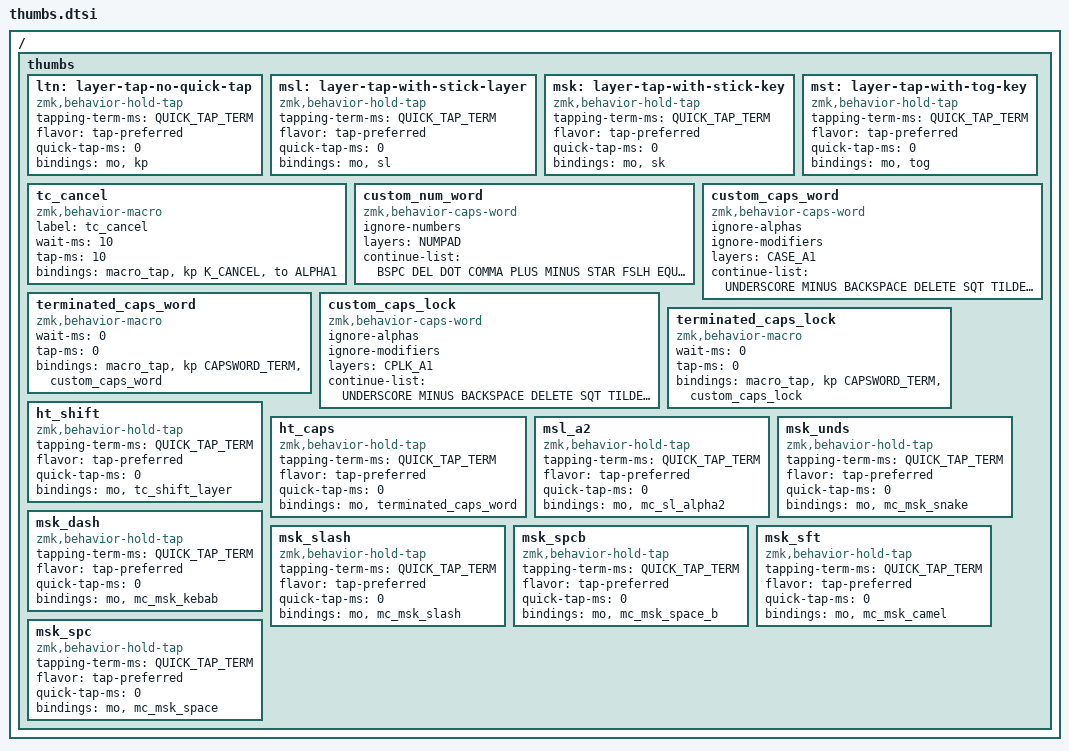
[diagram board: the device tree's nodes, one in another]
/*
*
* Copyright (c) 2022 Rafael Romão
* SPDX-License-Identifier: MIT
*
*/

/ {
    #define THUMB_LAYERTAP(NAME, BINDINGS) \
         NAME: NAME { \
            compatible = "zmk,behavior-hold-tap"; \
            #binding-cells = <2>; \
            tapping-term-ms = <QUICK_TAP_TERM>; \
            flavor = "tap-preferred"; \
            quick-tap-ms = <0>; \
            require-prior-idle-ms = <QUICK_TAP_TERM>; \
            bindings = <&mo>, <BINDINGS>; \
        };

    #define THUMB_MACRO(NAME, BINDINGS) \
        NAME: NAME { \
			compatible = "zmk,behavior-macro"; \
            #binding-cells = <0>; \
            wait-ms = <10>; \
            tap-ms = <10>; \
            bindings = <&macro_tap BINDINGS>; \
        };

    #define THUMB_MORPH(NAME, MODS, MODDED, UNMODDED) \
        NAME: NAME { \
            compatible = "zmk,behavior-mod-morph"; \
            #binding-cells = <0>; \
            bindings = <UNMODDED>, <MODDED>; \
            mods = <(MODS)>; \
        };

    #define THUMB_COMBO_MORPH(NAME, FIRST_MOD, SECOND_MOD, IF_BOTH, OR_ELSE) \
        NAME##_CHECK_SECOND: NAME##_CHECK_SECOND { \
            compatible = "zmk,behavior-mod-morph"; \
            #binding-cells = <0>; \
            bindings = <OR_ELSE>, <IF_BOTH>; \
            mods = <(SECOND_MOD)>; \
        }; \
        NAME: NAME { \
            compatible = "zmk,behavior-mod-morph"; \
            #binding-cells = <0>; \
            bindings = <OR_ELSE>, <&NAME##_CHECK_SECOND>; \
            mods = <(FIRST_MOD)>; \
        };

    thumbs {
        
        // ********************** CUSTOM HOLD TAPS ********************** //

        ltn: layer-tap-no-quick-tap {
            compatible = "zmk,behavior-hold-tap";
            #binding-cells = <2>;
            tapping-term-ms = <QUICK_TAP_TERM>;
            flavor = "tap-preferred";
            quick-tap-ms = <0>;
            bindings = <&mo>, <&kp>;
        };
        msl: layer-tap-with-stick-layer {
            compatible = "zmk,behavior-hold-tap";
            #binding-cells = <2>;
            tapping-term-ms = <QUICK_TAP_TERM>;
            flavor = "tap-preferred";
            quick-tap-ms = <0>;
            bindings = <&mo>, <&sl>;
        };
        msk: layer-tap-with-stick-key {
            compatible = "zmk,behavior-hold-tap";
            #binding-cells = <2>;
            tapping-term-ms = <QUICK_TAP_TERM>;
            flavor = "tap-preferred";
            quick-tap-ms = <0>;
            bindings = <&mo>, <&sk>;
        };
        mst: layer-tap-with-tog-key {
            compatible = "zmk,behavior-hold-tap";
            #binding-cells = <2>;
            tapping-term-ms = <QUICK_TAP_TERM>;
            flavor = "tap-preferred";
            quick-tap-ms = <0>;
            bindings = <&mo>, <&tog>;
        };

        // ********************** SENTENCE CASE ********************** //

        tc_cancel: tc_cancel {
			compatible = "zmk,behavior-macro";
            label = "tc_cancel";
            #binding-cells = <0>;
            wait-ms = <10>;
            tap-ms = <10>;
            bindings = <&macro_tap &kp K_CANCEL &to ALPHA1>;
        };
        THUMB_MACRO(tc_sp_ns,         &kp SPACE &sl SEN_E1)
        THUMB_MACRO(tc_nsen,          &sl SEN_E1)
        THUMB_LAYERTAP(th_sp_ns,      &tc_sp_ns)
        THUMB_LAYERTAP(th_cancel,     &tc_cancel)
        THUMB_LAYERTAP(th_nsen,       &tc_nsen)

        // ********************** NUM WORD ********************** //

        custom_num_word: custom_num_word {
            compatible = "zmk,behavior-caps-word";
            ignore-numbers;
			#binding-cells = <0>;
            layers = <NUMPAD>;
            continue-list = <BSPC DEL DOT COMMA PLUS MINUS STAR FSLH EQUAL MOVE_LEFT MOVE_RIGHT MOVE_UP MOVE_DOWN SCRL_DOWN SCRL_UP RCLK LCLK>;
        };

        THUMB_MACRO(tc_custom_num_word, &to ALPHA1 &custom_num_word)

        // ******************* CAPS WORD ******************* //

        custom_caps_word: custom_caps_word {
            compatible = "zmk,behavior-caps-word";
            ignore-alphas;
            ignore-modifiers;
			#binding-cells = <0>;  
            layers = <CASE_A1>;
            continue-list = <UNDERSCORE MINUS BACKSPACE DELETE SQT TILDE CARET GRAVE>;
        };
        terminated_caps_word: terminated_caps_word {
			compatible = "zmk,behavior-macro";
            #binding-cells = <0>;
            wait-ms = <0>;
            tap-ms = <0>;
            bindings = <&macro_tap &kp CAPSWORD_TERM &custom_caps_word>;
        };

        custom_caps_lock: custom_caps_lock {
            compatible = "zmk,behavior-caps-word";
            ignore-alphas;
            ignore-modifiers;
			#binding-cells = <0>;  
            layers = <CPLK_A1>;
            continue-list = <UNDERSCORE MINUS BACKSPACE DELETE SQT TILDE CARET GRAVE SPACE>;
        };
        terminated_caps_lock: terminated_caps_lock {
			compatible = "zmk,behavior-macro";
            #binding-cells = <0>;
            wait-ms = <0>;
            tap-ms = <0>;
            bindings = <&macro_tap &kp CAPSWORD_TERM &custom_caps_lock>;
        };

        THUMB_MACRO(tc_shift_layer, &sl SHIFT_A1)
        THUMB_MACRO(tc_sp_caps,     &kp LS(SPACE))
        THUMB_LAYERTAP(th_sp_caps,  &tc_sp_caps)

        ht_shift: ht_shift {
            compatible = "zmk,behavior-hold-tap";
            #binding-cells = <2>;
            tapping-term-ms = <QUICK_TAP_TERM>;
            flavor = "tap-preferred";
            quick-tap-ms = <0>;
            bindings = <&mo>, <&tc_shift_layer>;
        };

        ht_caps: ht_caps {
            compatible = "zmk,behavior-hold-tap";
            #binding-cells = <2>;
            tapping-term-ms = <QUICK_TAP_TERM>;
            flavor = "tap-preferred";
            quick-tap-ms = <0>;
            bindings = <&mo>, <&terminated_caps_word>;
        };

        // ******************** SMART CASES ******************** //

        THUMB_MACRO(mc_sl_alpha2,  &enforced_a2)

        THUMB_LAYERTAP(th_sft_a2,  &enforced_a2_s)
        THUMB_LAYERTAP(th_case_a2,  &enforced_a2_c)

        msl_a2: msl_a2 {
            compatible = "zmk,behavior-hold-tap";
            #binding-cells = <2>;
            tapping-term-ms = <QUICK_TAP_TERM>;
            flavor = "tap-preferred";
            quick-tap-ms = <0>;
            bindings = <&mo>, <&mc_sl_alpha2>;
        };

        THUMB_MACRO(tc_shift_camel     ,  &to CAMEL_CASE &sl SHIFT_A1)
        THUMB_MACRO(tc_strong_snakecase,  &tog CASE_A1 &tog SNAKE_CASE)
        THUMB_MACRO(tc_strong_kebabcase,  &tog CASE_A1 &tog KEBAB_CASE)
        THUMB_MACRO(tc_strong_slashcase,  &tog CASE_A1 &tog SLASH_CASE)

        THUMB_MORPH(sc_caps_word,  MOD_LCTL, &terminated_caps_word , &msl_a2 RAISE 0 )
        THUMB_MORPH(sc_caps_lock,  MOD_RCTL, &terminated_caps_lock , &sc_caps_word   )
        THUMB_MORPH(sc_numpad,     MOD_LALT, &to NUMPAD            , &sc_caps_lock   )
        THUMB_MORPH(sc_numword,    MOD_RALT, &custom_num_word      , &sc_numpad      )
        THUMB_MORPH(sc_camelcase,  MOD_LSFT, &to CAMEL_CASE        , &sc_numword     )
        THUMB_MORPH(sc_snakecase,  MOD_LGUI, &to SNAKE_CASE        , &sc_camelcase   )
        THUMB_MORPH(sc_kebabcase,  MOD_RGUI, &to KEBAB_CASE        , &sc_snakecase   )
        THUMB_MORPH(sc_slashcase,  MOD_RSFT, &to SLASH_CASE        , &sc_kebabcase   )

        THUMB_COMBO_MORPH(sc_pascalcase       , MOD_LCTL, MOD_LSFT, &tc_shift_camel     , &sc_slashcase)
        THUMB_COMBO_MORPH(sc_strong_snake_case, MOD_LCTL, MOD_LGUI, &tc_strong_snakecase, &sc_pascalcase)
        THUMB_COMBO_MORPH(sc_strong_kebab_case, MOD_RCTL, MOD_RGUI, &tc_strong_kebabcase, &sc_strong_snake_case)
        THUMB_COMBO_MORPH(sc_strong_slash_case, MOD_RCTL, MOD_RSFT, &tc_strong_slashcase, &sc_strong_kebab_case)
        
        #define msl_raise_smart sc_strong_slash_case

        THUMB_MACRO(mc_msk_camel, &sl SHIFT_A1)
        THUMB_MACRO(mc_msk_snake, &kp UNDERSCORE &sl SPACING)
        THUMB_MACRO(mc_msk_kebab, &kp MINUS &sl SPACING)
        THUMB_MACRO(mc_msk_slash, &kp SLASH &sl SPACING)
        THUMB_MACRO(mc_msk_space, &kp SPACE &to ALPHA1)
        THUMB_MACRO(mc_msk_space_b, &kp BACKSPACE &kp SPACE &to ALPHA1)

        msk_unds: msk_unds {
            compatible = "zmk,behavior-hold-tap";
            #binding-cells = <2>;
            tapping-term-ms = <QUICK_TAP_TERM>;
            flavor = "tap-preferred";
            quick-tap-ms = <0>;
            bindings = <&mo>, <&mc_msk_snake>;
        };

        msk_dash: msk_dash {
            compatible = "zmk,behavior-hold-tap";
            #binding-cells = <2>;
            tapping-term-ms = <QUICK_TAP_TERM>;
            flavor = "tap-preferred";
            quick-tap-ms = <0>;
            bindings = <&mo>, <&mc_msk_kebab>;
        };

        msk_slash: msk_slash {
            compatible = "zmk,behavior-hold-tap";
            #binding-cells = <2>;
            tapping-term-ms = <QUICK_TAP_TERM>;
            flavor = "tap-preferred";
            quick-tap-ms = <0>;
            bindings = <&mo>, <&mc_msk_slash>;
        };

        msk_spcb: msk_spcb {
            compatible = "zmk,behavior-hold-tap";
            #binding-cells = <2>;
            tapping-term-ms = <QUICK_TAP_TERM>;
            flavor = "tap-preferred";
            quick-tap-ms = <0>;
            bindings = <&mo>, <&mc_msk_space_b>;
        };

        msk_sft: msk_sft {
            compatible = "zmk,behavior-hold-tap";
            #binding-cells = <2>;
            tapping-term-ms = <QUICK_TAP_TERM>;
            flavor = "tap-preferred";
            quick-tap-ms = <0>;
            bindings = <&mo>, <&mc_msk_camel>;
        };

        msk_spc: msk_spc {
            compatible = "zmk,behavior-hold-tap";
            #binding-cells = <2>;
            tapping-term-ms = <QUICK_TAP_TERM>;
            flavor = "tap-preferred";
            quick-tap-ms = <0>;
            bindings = <&mo>, <&mc_msk_space>;
        };

    };
};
